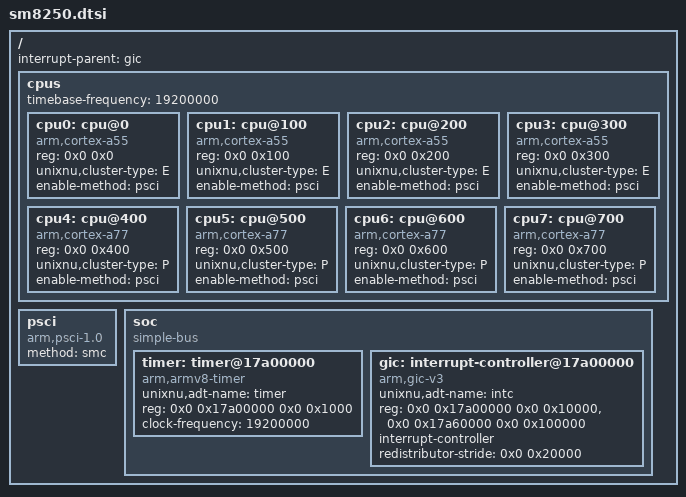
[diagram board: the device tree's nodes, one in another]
// SPDX-License-Identifier: BSD-2-Clause-Patent
// Shared SM8250/Kona facts measured from the J716F firmware DT + 8-core E/P topology.
/ {
    #address-cells = <2>;
    #size-cells = <2>;
    interrupt-parent = <&gic>;

    cpus {
        #address-cells = <2>;
        #size-cells = <0>;
        timebase-frequency = <19200000>;

        cpu0: cpu@0 {
            device_type = "cpu";
            compatible = "arm,cortex-a55";
            reg = <0x0 0x0>;
            unixnu,cluster-type = "E";
            enable-method = "psci";
            status = "okay";
        };

        cpu1: cpu@100 {
            device_type = "cpu";
            compatible = "arm,cortex-a55";
            reg = <0x0 0x100>;
            unixnu,cluster-type = "E";
            enable-method = "psci";
            status = "okay";
        };

        cpu2: cpu@200 {
            device_type = "cpu";
            compatible = "arm,cortex-a55";
            reg = <0x0 0x200>;
            unixnu,cluster-type = "E";
            enable-method = "psci";
            status = "okay";
        };

        cpu3: cpu@300 {
            device_type = "cpu";
            compatible = "arm,cortex-a55";
            reg = <0x0 0x300>;
            unixnu,cluster-type = "E";
            enable-method = "psci";
            status = "okay";
        };

        cpu4: cpu@400 {
            device_type = "cpu";
            compatible = "arm,cortex-a77";
            reg = <0x0 0x400>;
            unixnu,cluster-type = "P";
            enable-method = "psci";
            status = "okay";
        };

        cpu5: cpu@500 {
            device_type = "cpu";
            compatible = "arm,cortex-a77";
            reg = <0x0 0x500>;
            unixnu,cluster-type = "P";
            enable-method = "psci";
            status = "okay";
        };

        cpu6: cpu@600 {
            device_type = "cpu";
            compatible = "arm,cortex-a77";
            reg = <0x0 0x600>;
            unixnu,cluster-type = "P";
            enable-method = "psci";
            status = "okay";
        };

        cpu7: cpu@700 {
            device_type = "cpu";
            compatible = "arm,cortex-a77";
            reg = <0x0 0x700>;
            unixnu,cluster-type = "P";
            enable-method = "psci";
            status = "okay";
        };
    };

    psci {
        compatible = "arm,psci-1.0";
        method = "smc";
    };

    soc {
        compatible = "simple-bus";
        #address-cells = <2>;
        #size-cells = <2>;
        ranges;

        timer: timer@17a00000 {
            unixnu,adt-name = "timer";
            device_type = "timer";
            compatible = "arm,armv8-timer";
            reg = <0x0 0x17a00000 0x0 0x1000>;
            clock-frequency = <19200000>;
            // Binding order and flags independently agree in stock/recovery FDT.
            // Virtual timer: PPI11 -> INTID27 (scripts/j716f-native-timer-route.json).
            // interrupts removed for IOKit start-up compatibility
            status = "okay";
        };

        gic: interrupt-controller@17a00000 {
            compatible = "arm,gic-v3";
            unixnu,adt-name = "intc";
            reg = <0x0 0x17a00000 0x0 0x10000>,
                  <0x0 0x17a60000 0x0 0x100000>;
            #interrupt-cells = <3>;
            #address-cells = <0>;
            interrupt-controller;
            redistributor-stride = <0x0 0x20000>;
            status = "okay";
        };
    };
};
